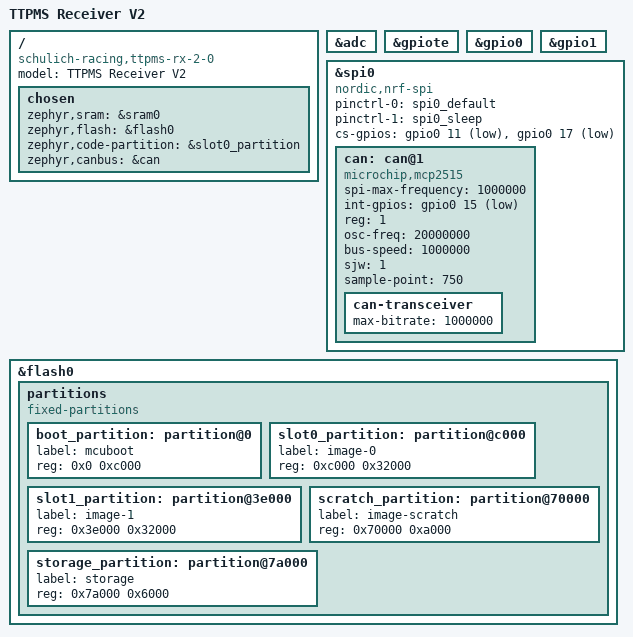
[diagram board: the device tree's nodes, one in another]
// Copyright (c) 2023 Nordic Semiconductor ASA
// SPDX-License-Identifier: Apache-2.0

/dts-v1/;
#include <nordic/nrf52833_qiaa.dtsi>
#include "ttpms_rx_2_0-pinctrl.dtsi"

/ {
	model = "TTPMS Receiver V2";
	compatible = "schulich-racing,ttpms-rx-2-0";

	chosen {
		zephyr,sram = &sram0;
		zephyr,flash = &flash0;
		zephyr,code-partition = &slot0_partition;
		zephyr,canbus = &can;
	};
};

&adc {
	status = "okay";
};

&gpiote {
	status = "okay";
};

&gpio0 {
	status = "okay";
};

&gpio1 {
	status = "okay";
};

&spi0 {
	compatible = "nordic,nrf-spi";
	status = "okay";
	pinctrl-0 = <&spi0_default>;
	pinctrl-1 = <&spi0_sleep>;
	pinctrl-names = "default", "sleep";

	cs-gpios = <&gpio0 11 GPIO_ACTIVE_LOW>,		// SD card CS on P0.11
			   <&gpio0 17 GPIO_ACTIVE_LOW>;		// MCP2515 CS on P0.17

	/*	CS AND MOSI SD CONNECTOR PINS ARE SWAPPED LOL RIP
	sdhc: sdhc@0 {
		compatible = "zephyr,sdhc-spi-slot";
		reg = <0>;		// use first CS pin (see cs-gpios above)
		status = "okay";
		//spi-max-frequency = <24000000>;		// 24MHz (not tested)
		spi-max-frequency = <400000>;			// 400KHz
		mmc {
			compatible = "zephyr,sdmmc-disk";
			status = "okay";
		};
	};*/

	can: can@1 {
		compatible = "microchip,mcp2515";
		status = "okay";
		//spi-max-frequency = <10000000>;		// 10MHz (not tested, examples use 1MHz)
		spi-max-frequency = <1000000>;			// 1MHz
		int-gpios = <&gpio0 15 GPIO_ACTIVE_LOW>;	// interupt on P0.15
		reg = <1>;			// use second CS pin (see cs-gpios above)
		osc-freq = <20000000>;	// 20MHz oscillator
		bus-speed = <1000000>;	// 1Mbps
		sjw = <1>;
		sample-point = <750>;	// 75% sample point

		can-transceiver {		// idk why this is getting the red squiggly, it should not
			max-bitrate = <1000000>;
		};
	};
};

&flash0 {
	partitions {
		compatible = "fixed-partitions";
		#address-cells = <1>;
		#size-cells = <1>;

		boot_partition: partition@0 {
			label = "mcuboot";
			reg = <0x0 0xc000>;
		};
		slot0_partition: partition@c000 {
			label = "image-0";
			reg = <0xc000 0x32000>;
		};
		slot1_partition: partition@3e000 {
			label = "image-1";
			reg = <0x3e000 0x32000>;
		};
		scratch_partition: partition@70000 {
			label = "image-scratch";
			reg = <0x70000 0xa000>;
		};
		storage_partition: partition@7a000 {
			label = "storage";
			reg = <0x7a000 0x6000>;
		};
	};
};

